# STM32L471QEI3 register map
File version: 1.0
Registers are 32-bit, access not given, reset 0x0 unless marked. A register's access mark holds for its fields unless they carry their own. Offsets are from the block's base; [hi:lo] are bit positions; {n}, {i} and the like mark numbered series; 'fields as' and 'values as' point back to an identical list.

## TIM15
Base 0x40014000
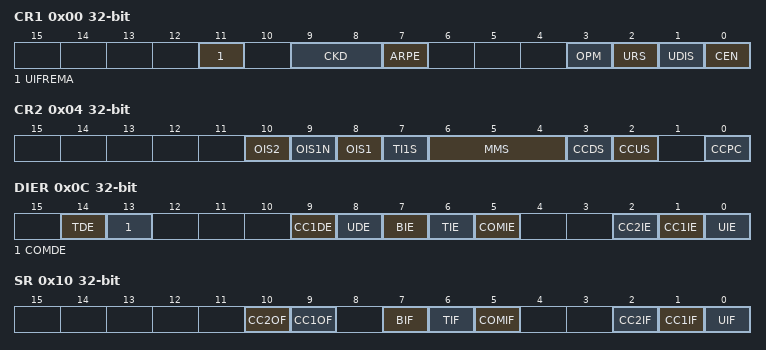
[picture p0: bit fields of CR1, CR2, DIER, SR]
0x00 CR1
  [11] UIFREMA, [9:8] CKD, [7] ARPE, [3] OPM, [2] URS, [1] UDIS, [0] CEN
0x04 CR2
  [10] OIS2, [9] OIS1N, [8] OIS1, [7] TI1S, [6:4] MMS, [3] CCDS, [2] CCUS, [0] CCPC
0x08 SMCR
  [7] MSM, [6:4] TS, [16:0] SMS
0x0C DIER
  [14] TDE, [13] COMDE, [9] CC1DE, [8] UDE, [7] BIE, [6] TIE, [5] COMIE, [2] CC2IE, [1] CC1IE, [0] UIE
0x10 SR
  [10] CC2OF, [9] CC1OF, [7] BIF, [6] TIF, [5] COMIF, [2] CC2IF, [1] CC1IF, [0] UIF
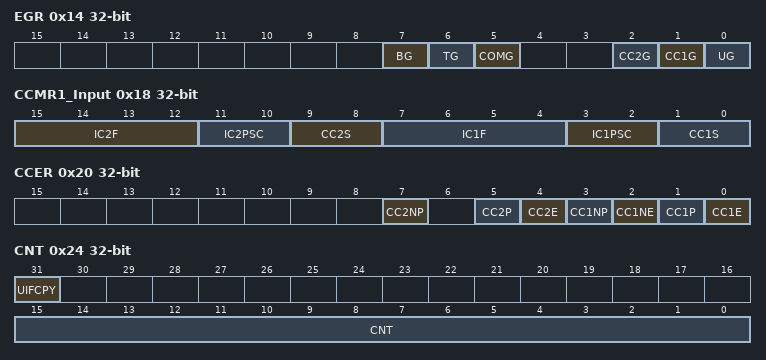
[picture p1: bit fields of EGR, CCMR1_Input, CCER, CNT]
0x14 EGR
  [7] BG, [6] TG, [5] COMG, [2] CC2G, [1] CC1G, [0] UG
0x18 CCMR1_Output
  [24:12] OC2M, [11] OC2PE, [10] OC2FE, [9:8] CC2S, [16:4] OC1M, [3] OC1PE, [2] OC1FE, [1:0] CC1S
0x18 CCMR1_Input
  [15:12] IC2F, [11:10] IC2PSC, [9:8] CC2S, [7:4] IC1F, [3:2] IC1PSC, [1:0] CC1S
0x20 CCER
  [7] CC2NP, [5] CC2P, [4] CC2E, [3] CC1NP, [2] CC1NE, [1] CC1P, [0] CC1E
0x24 CNT
  [31] UIFCPY, [15:0] CNT
0x28 PSC
  [15:0] PSC
0x2C ARR
  [15:0] ARR
0x30 RCR
  [7:0] REP
0x34 CCR1
  [15:0] CCR1
0x38 CCR2
  [15:0] CCR2
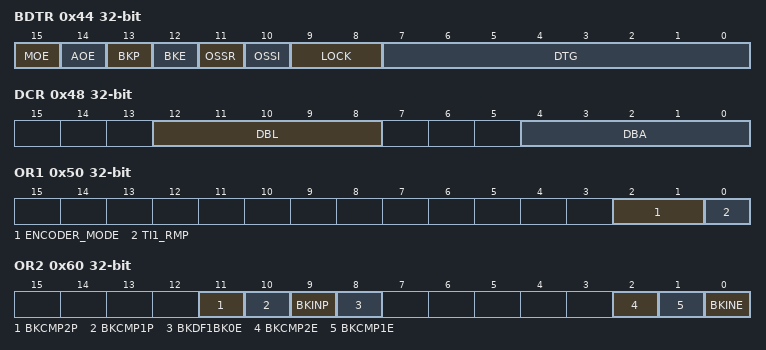
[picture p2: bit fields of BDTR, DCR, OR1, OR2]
0x44 BDTR
  [15] MOE, [14] AOE, [13] BKP, [12] BKE, [11] OSSR, [10] OSSI, [9:8] LOCK, [7:0] DTG
0x48 DCR
  [12:8] DBL, [4:0] DBA
0x4C DMAR
  [15:0] DMAB
0x50 OR1
  [2:1] ENCODER_MODE, [0] TI1_RMP
0x60 OR2
  [11] BKCMP2P, [10] BKCMP1P, [9] BKINP, [8] BKDF1BK0E, [2] BKCMP2E, [1] BKCMP1E, [0] BKINE

## TIM16
Base 0x40014400
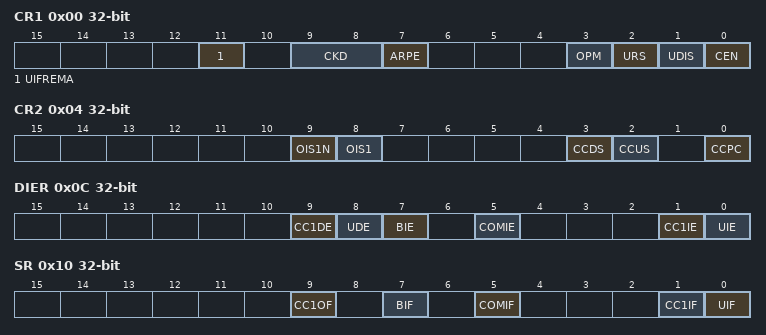
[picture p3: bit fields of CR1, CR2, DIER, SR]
0x00 CR1
  [11] UIFREMA, [9:8] CKD, [7] ARPE, [3] OPM, [2] URS, [1] UDIS, [0] CEN
0x04 CR2
  [9] OIS1N, [8] OIS1, [3] CCDS, [2] CCUS, [0] CCPC
0x0C DIER
  [9] CC1DE, [8] UDE, [7] BIE, [5] COMIE, [1] CC1IE, [0] UIE
0x10 SR
  [9] CC1OF, [7] BIF, [5] COMIF, [1] CC1IF, [0] UIF
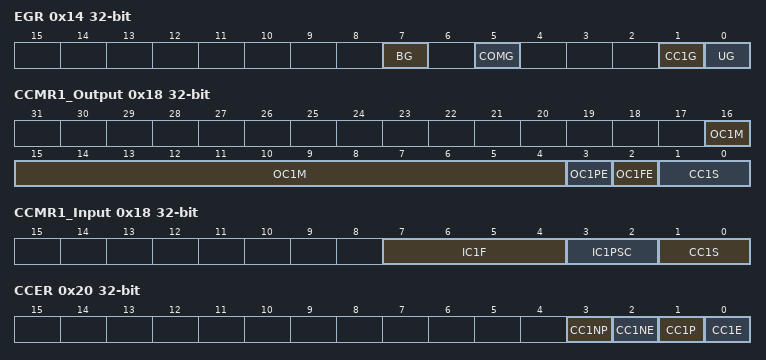
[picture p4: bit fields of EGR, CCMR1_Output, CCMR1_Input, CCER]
0x14 EGR
  [7] BG, [5] COMG, [1] CC1G, [0] UG
0x18 CCMR1_Output
  [16:4] OC1M, [3] OC1PE, [2] OC1FE, [1:0] CC1S
0x18 CCMR1_Input
  [7:4] IC1F, [3:2] IC1PSC, [1:0] CC1S
0x20 CCER
  [3] CC1NP, [2] CC1NE, [1] CC1P, [0] CC1E
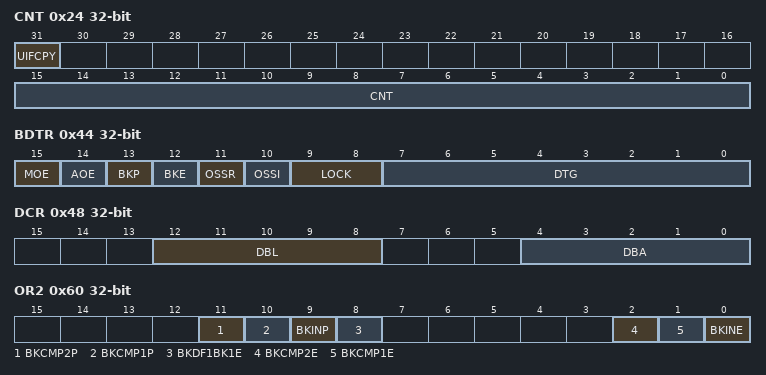
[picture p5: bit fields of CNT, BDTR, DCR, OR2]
0x24 CNT
  [31] UIFCPY, [15:0] CNT
0x28 PSC
  [15:0] PSC
0x2C ARR
  [15:0] ARR
0x30 RCR
  [7:0] REP
0x34 CCR1
  [15:0] CCR1
0x44 BDTR
  [15] MOE, [14] AOE, [13] BKP, [12] BKE, [11] OSSR, [10] OSSI, [9:8] LOCK, [7:0] DTG
0x48 DCR
  [12:8] DBL, [4:0] DBA
0x4C DMAR
  [15:0] DMAB
0x50 OR1
  [1:0] TI1_RMP
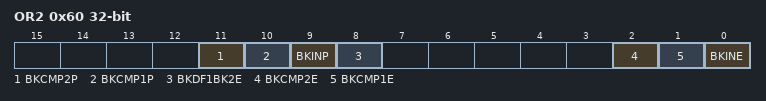
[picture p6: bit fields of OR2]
0x60 OR2
  [11] BKCMP2P, [10] BKCMP1P, [9] BKINP, [8] BKDF1BK1E, [2] BKCMP2E, [1] BKCMP1E, [0] BKINE

## TIM17
Base 0x40014800
Registers as TIM16; these are added or differ:
0x60 OR2
  [11] BKCMP2P, [10] BKCMP1P, [9] BKINP, [8] BKDF1BK2E, [2] BKCMP2E, [1] BKCMP1E, [0] BKINE

## SAI1
Base 0x40015400
Same registers: SAI2 0x40015800
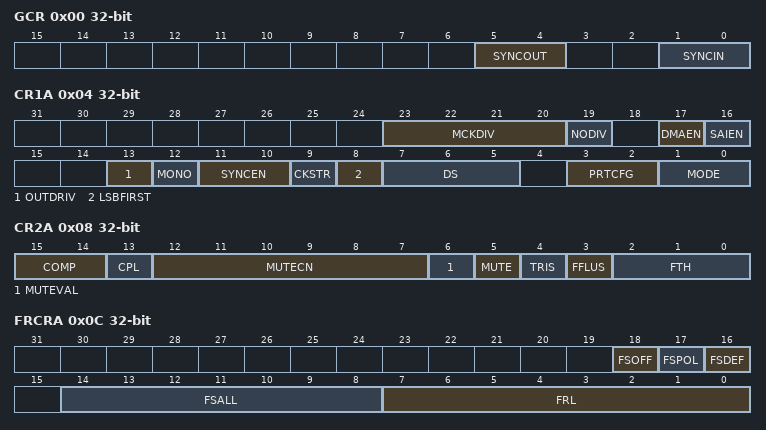
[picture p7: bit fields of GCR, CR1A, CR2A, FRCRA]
0x00 GCR
  [5:4] SYNCOUT, [1:0] SYNCIN
0x04 CR1A
  [23:20] MCKDIV, [19] NODIV, [17] DMAEN, [16] SAIEN, [13] OUTDRIV, [12] MONO, [11:10] SYNCEN, [9] CKSTR, [8] LSBFIRST, [7:5] DS, [3:2] PRTCFG, [1:0] MODE
0x08 CR2A
  [15:14] COMP, [13] CPL, [12:7] MUTECN, [6] MUTEVAL, [5] MUTE, [4] TRIS, [3] FFLUS, [2:0] FTH
0x0C FRCRA
  [18] FSOFF, [17] FSPOL, [16] FSDEF, [14:8] FSALL, [7:0] FRL
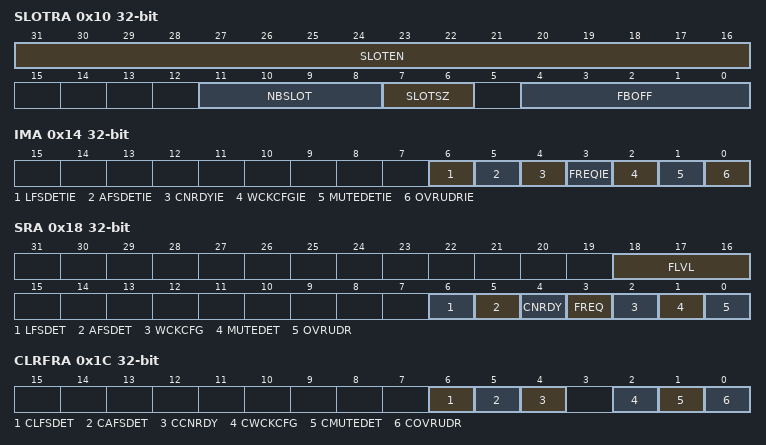
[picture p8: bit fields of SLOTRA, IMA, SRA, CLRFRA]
0x10 SLOTRA
  [31:16] SLOTEN, [11:8] NBSLOT, [7:6] SLOTSZ, [4:0] FBOFF
0x14 IMA
  [6] LFSDETIE, [5] AFSDETIE, [4] CNRDYIE, [3] FREQIE, [2] WCKCFGIE, [1] MUTEDETIE, [0] OVRUDRIE
0x18 SRA
  [18:16] FLVL, [6] LFSDET, [5] AFSDET, [4] CNRDY, [3] FREQ, [2] WCKCFG, [1] MUTEDET, [0] OVRUDR
0x1C CLRFRA
  [6] CLFSDET, [5] CAFSDET, [4] CCNRDY, [2] CWCKCFG, [1] CMUTEDET, [0] COVRUDR
0x20 DRA
  [31:0] DATA
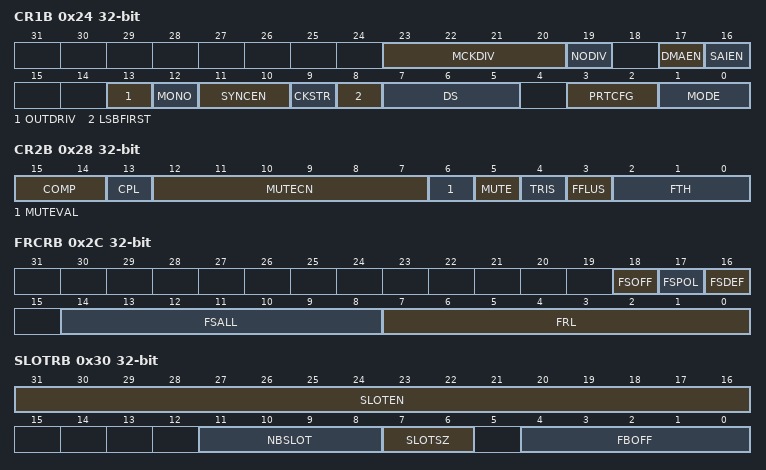
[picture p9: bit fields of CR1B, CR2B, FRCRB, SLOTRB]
0x24 CR1B
  fields as CR1A
0x28 CR2B
  fields as CR2A
0x2C FRCRB
  [18] FSOFF, [17] FSPOL, [16] FSDEF, [14:8] FSALL, [7:0] FRL
0x30 SLOTRB
  [31:16] SLOTEN, [11:8] NBSLOT, [7:6] SLOTSZ, [4:0] FBOFF
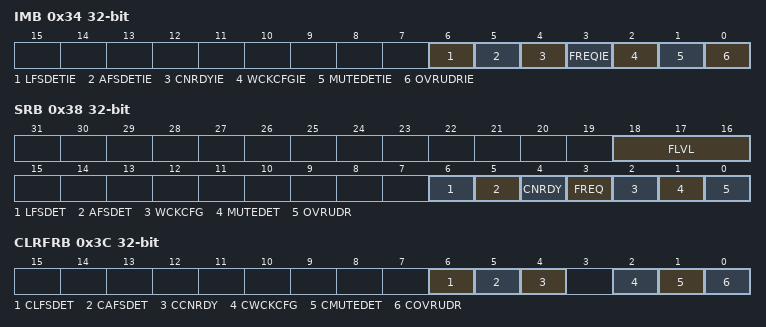
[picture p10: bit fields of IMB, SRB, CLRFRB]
0x34 IMB
  fields as IMA
0x38 SRB
  fields as SRA
0x3C CLRFRB
  fields as CLRFRA
0x40 DRB
  [31:0] DATA

## DFSDM1
Base 0x40016000
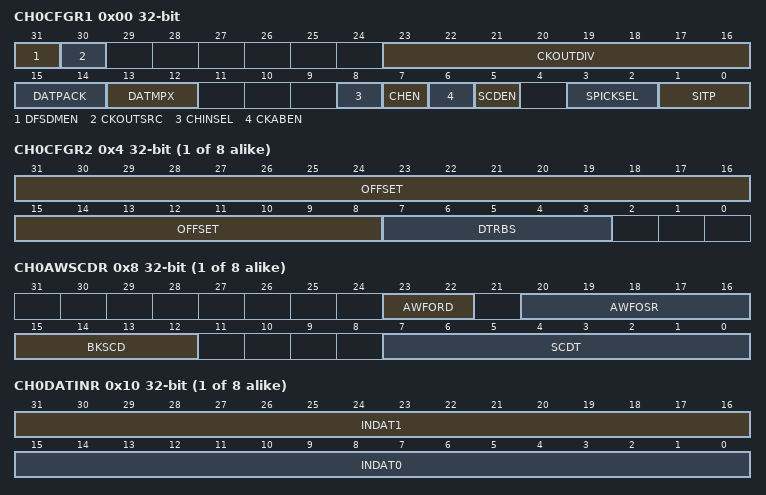
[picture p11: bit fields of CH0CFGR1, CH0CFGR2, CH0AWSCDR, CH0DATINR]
0x00 CH0CFGR1
  [31] DFSDMEN, [30] CKOUTSRC, [23:16] CKOUTDIV, [15:14] DATPACK, [13:12] DATMPX, [8] CHINSEL, [7] CHEN, [6] CKABEN, [5] SCDEN, [3:2] SPICKSEL, [1:0] SITP
{0x4+0x20*i} CH{i}CFGR2 (i=0..7)
  [31:8] OFFSET, [7:3] DTRBS
{0x8+0x20*i} CH{i}AWSCDR (i=0..7)
  [23:22] AWFORD, [20:16] AWFOSR, [15:12] BKSCD, [7:0] SCDT
{0xC+0x20*i} CH{i}WDATR (i=0..7)
  [15:0] WDATA
{0x10+0x20*i} CH{i}DATINR (i=0..7)
  [31:16] INDAT1, [15:0] INDAT0
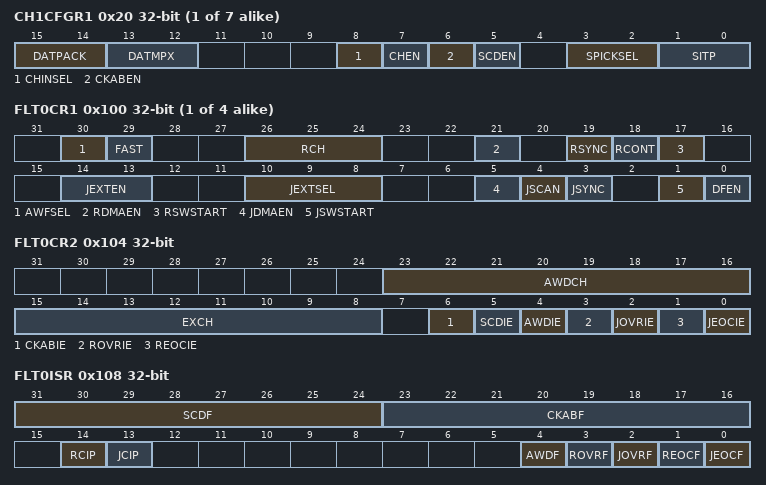
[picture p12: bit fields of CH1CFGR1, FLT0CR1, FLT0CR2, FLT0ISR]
{0x0+0x20*i} CH{i}CFGR1 (i=1..7)
  [15:14] DATPACK, [13:12] DATMPX, [8] CHINSEL, [7] CHEN, [6] CKABEN, [5] SCDEN, [3:2] SPICKSEL, [1:0] SITP
{0x100+0x80*i} FLT{i}CR1 (i=0..3)
  [30] AWFSEL, [29] FAST, [26:24] RCH, [21] RDMAEN, [19] RSYNC, [18] RCONT, [17] RSWSTART, [14:13] JEXTEN, [10:8] JEXTSEL, [5] JDMAEN, [4] JSCAN, [3] JSYNC, [1] JSWSTART, [0] DFEN
0x104 FLT0CR2
  [23:16] AWDCH, [15:8] EXCH, [6] CKABIE, [5] SCDIE, [4] AWDIE, [3] ROVRIE, [2] JOVRIE, [1] REOCIE, [0] JEOCIE
0x108 FLT0ISR
  [31:24] SCDF, [23:16] CKABF, [14] RCIP, [13] JCIP, [4] AWDF, [3] ROVRF, [2] JOVRF, [1] REOCF, [0] JEOCF
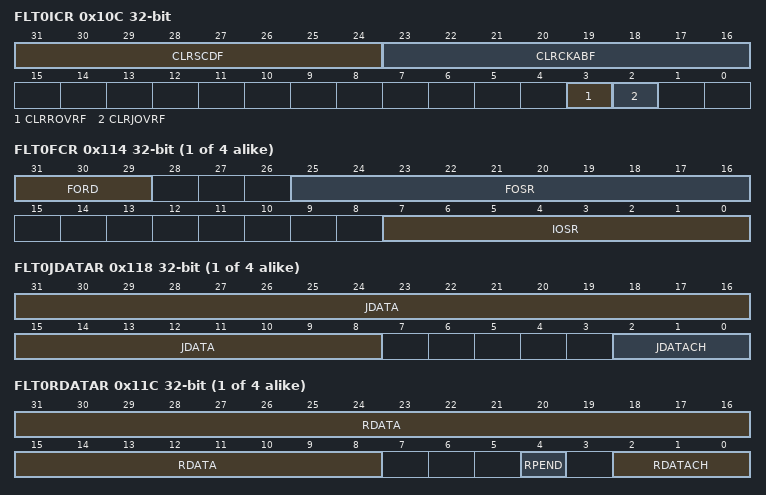
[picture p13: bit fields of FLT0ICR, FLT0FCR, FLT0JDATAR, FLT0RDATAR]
0x10C FLT0ICR
  [31:24] CLRSCDF, [23:16] CLRCKABF, [3] CLRROVRF, [2] CLRJOVRF
{0x110+0x80*i} FLT{i}JCHGR (i=0..3)
  [7:0] JCHG
{0x114+0x80*i} FLT{i}FCR (i=0..3)
  [31:29] FORD, [25:16] FOSR, [7:0] IOSR
{0x118+0x80*i} FLT{i}JDATAR (i=0..3)
  [31:8] JDATA, [2:0] JDATACH
{0x11C+0x80*i} FLT{i}RDATAR (i=0..3)
  [31:8] RDATA, [4] RPEND, [2:0] RDATACH
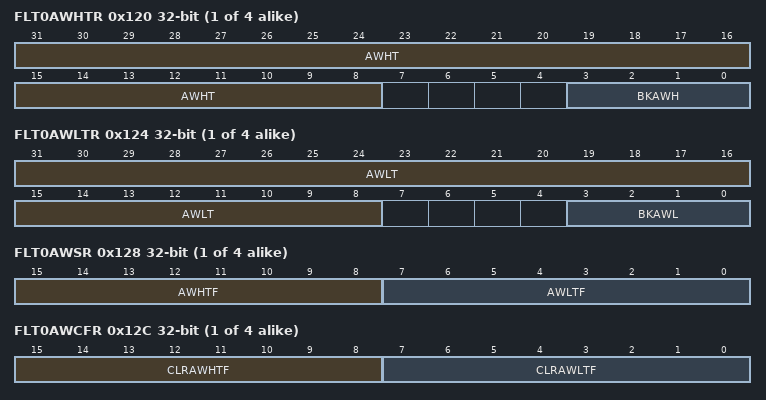
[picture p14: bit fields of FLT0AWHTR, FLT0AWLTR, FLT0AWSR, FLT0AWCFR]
{0x120+0x80*i} FLT{i}AWHTR (i=0..3)
  [31:8] AWHT, [3:0] BKAWH
{0x124+0x80*i} FLT{i}AWLTR (i=0..3)
  [31:8] AWLT, [3:0] BKAWL
{0x128+0x80*i} FLT{i}AWSR (i=0..3)
  [15:8] AWHTF, [7:0] AWLTF
{0x12C+0x80*i} FLT{i}AWCFR (i=0..3)
  [15:8] CLRAWHTF, [7:0] CLRAWLTF
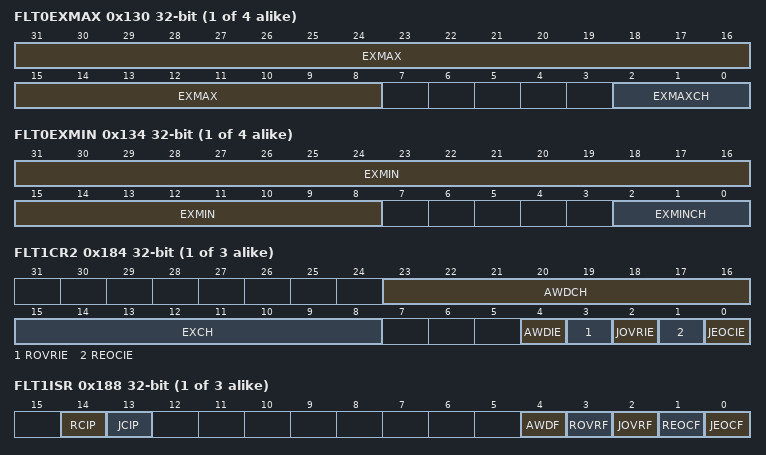
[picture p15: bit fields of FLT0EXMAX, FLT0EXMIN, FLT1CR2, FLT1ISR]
{0x130+0x80*i} FLT{i}EXMAX (i=0..3)
  [31:8] EXMAX, [2:0] EXMAXCH
{0x134+0x80*i} FLT{i}EXMIN (i=0..3)
  [31:8] EXMIN, [2:0] EXMINCH
{0x138+0x80*i} FLT{i}CNVTIMR (i=0..3)
  [31:4] CNVCNT
{0x104+0x80*i} FLT{i}CR2 (i=1..3)
  [23:16] AWDCH, [15:8] EXCH, [4] AWDIE, [3] ROVRIE, [2] JOVRIE, [1] REOCIE, [0] JEOCIE
{0x108+0x80*i} FLT{i}ISR (i=1..3)
  [14] RCIP, [13] JCIP, [4] AWDF, [3] ROVRF, [2] JOVRF, [1] REOCF, [0] JEOCF
{0x10C+0x80*i} FLT{i}ICR (i=1..3)
  [3] CLRROVRF, [2] CLRJOVRF
